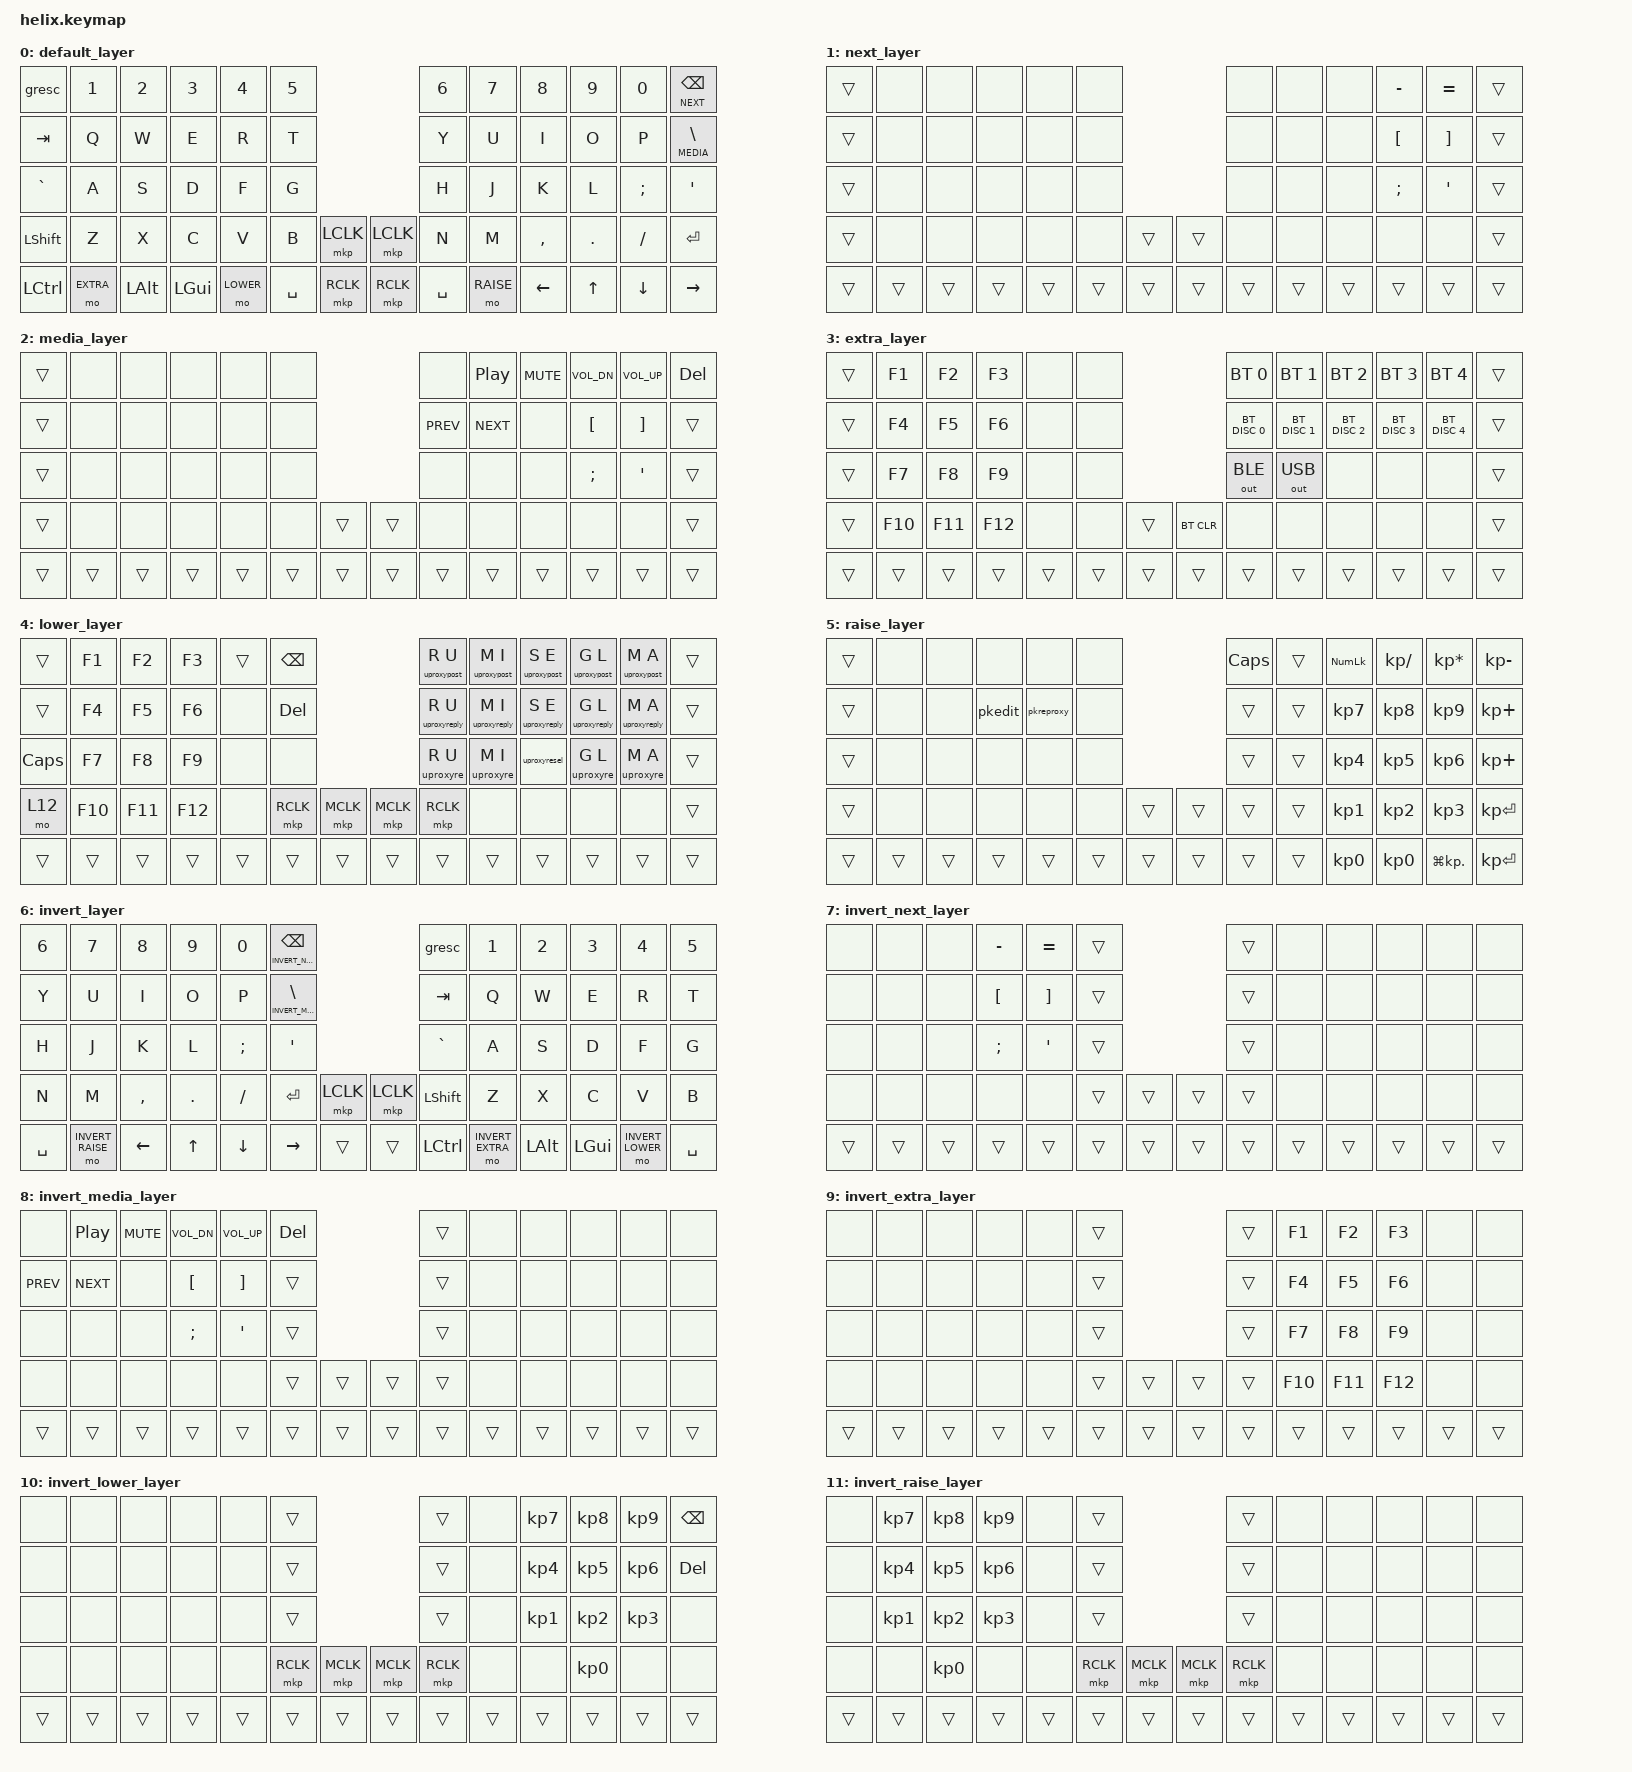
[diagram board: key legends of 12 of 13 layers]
/*
 * Copyright (c) 2020 The ZMK Contributors
 *
 * SPDX-License-Identifier: MIT
 */

#include <dt-bindings/zmk/mouse.h>
#include <behaviors.dtsi>
#include <dt-bindings/zmk/bt.h>
#include <dt-bindings/zmk/keys.h>
#include <dt-bindings/zmk/outputs.h>
#include <dt-bindings/zmk/pointing.h>

#define DEFAULT 0
#define NEXT 1
#define MEDIA 2
#define EXTRA 3
#define LOWER  4
#define RAISE  5
#define INVERT 6
#define INVERT_NEXT 7
#define INVERT_MEDIA 8
#define INVERT_EXTRA 9
#define INVERT_LOWER 10
#define INVERT_RAISE 11

/ {
    macros {
        qmaddie: qmaddie {
            compatible = "zmk,behavior-macro";
            #binding-cells = <0>;
            bindings = <&kp M &kp A &kp D &kp D &kp I &kp E &kp COLON &kp RET &kp GT &kp SPACE>;
            label = "QMADDIE";
        };

        qruby: qruby {
            compatible = "zmk,behavior-macro";
            #binding-cells = <0>;
            bindings = <&kp LS(R) &kp U &kp B &kp Y &kp COLON &kp RET &kp GT &kp SPACE>;
            label = "QRUBY";
        };

        qglimmer: qglimmer {
            compatible = "zmk,behavior-macro";
            #binding-cells = <0>;
            bindings = <&kp LS(G) &kp L &kp I &kp M &kp M &kp E &kp R &kp COLON &kp RET &kp GT &kp SPACE>;
            label = "QGLIMMER";
        };

        qselphie: qselphie {
            compatible = "zmk,behavior-macro";
            #binding-cells = <0>;
            bindings = <&kp LS(S) &kp E &kp L &kp P &kp H &kp I &kp E &kp COLON &kp RET &kp GT &kp SPACE>;
            label = "QSELPHIE";
        };

        qmio: qmio {
            compatible = "zmk,behavior-macro";
            #binding-cells = <0>;
            bindings = <&kp LS(M) &kp I &kp O &kp COLON &kp RET &kp GT &kp SPACE>;
            label = "QMIO";
        };

        pkreproxy: pkreproxy {
            compatible = "zmk,behavior-macro";
            #binding-cells = <0>;
            bindings = <&kp P &kp K &kp SEMI &kp R &kp E &kp P &kp R &kp O &kp X &kp Y &kp SPACE>;
            label = "PKREPROXY";
        };

        pkedit: pkedit {
            compatible = "zmk,behavior-macro";
            #binding-cells = <0>;
            bindings = <&kp P &kp K &kp SEMI &kp E &kp SPACE>;
            label = "PKEDIT";
        };

        pkremaddie: pkremaddie {
            compatible = "zmk,behavior-macro";
            #binding-cells = <0>;
            bindings = <&pkreproxy &kp M &kp A &kp D &kp D &kp I &kp E &kp RET>;
            label = "PKREMADDIE";
        };

        pkreglimmer: pkreglimmer {
            compatible = "zmk,behavior-macro";
            #binding-cells = <0>;
            bindings = <&pkreproxy &kp G &kp L &kp I &kp M &kp M &kp E &kp R &kp RET>;
            label = "PKREGLIMMER";
        };

        pkreselphie: pkreselphie {
            compatible = "zmk,behavior-macro";
            #binding-cells = <0>;
            bindings = <&pkreproxy &kp S &kp E &kp L &kp P &kp H &kp I &kp E &kp RET>;
            label = "PKRESELPHIE";
        };

        pkremio: pkremio {
            compatible = "zmk,behavior-macro";
            #binding-cells = <0>;
            bindings = <&pkreproxy &kp M &kp I &kp O &kp RET>;
            label = "PKREMIO";
        };

        pkreruby: pkreruby {
            compatible = "zmk,behavior-macro";
            #binding-cells = <0>;
            bindings = <&pkreproxy &kp R &kp U &kp B &kp Y &kp RET>;
            label = "PKRERUBY";
        };

        uproxyreply: uproxy {
            compatible = "zmk,behavior-macro-two-param";
            #binding-cells = <2>;
            bindings = <&kp FSLH &macro_param_1to1 &kp MACRO_PLACEHOLDER &macro_param_2to1 &kp MACRO_PLACEHOLDER &kp TAB &kp Q &kp TAB &kp T &kp TAB &kp M &kp TAB>;
            label = "UPROXY";
        };

        uproxypost: uproxypost {
            compatible = "zmk,behavior-macro-two-param";
            #binding-cells = <2>;
            bindings = <&kp FSLH &macro_param_1to1 &kp MACRO_PLACEHOLDER &macro_param_2to1 &kp MACRO_PLACEHOLDER &kp TAB &kp M &kp TAB>;
            label = "UPROXYPOST";
        };

        uproxyre: uproxyre {
            compatible = "zmk,behavior-macro-two-param";
            #binding-cells = <2>;
            bindings = <&kp FSLH &kp R &kp E &kp P &kp R &kp O &kp X &kp Y &kp TAB &macro_param_1to1 &kp MACRO_PLACEHOLDER &macro_param_2to1 &kp MACRO_PLACEHOLDER>;
            label = "UPROXYRE";
        };

        uproxyresel: uproxyresel {
            compatible = "zmk,behavior-macro";
            #binding-cells = <0>;
            bindings = <&uproxyre S E &kp L>;
            label = "UPROXYRESEL";
        };

        pkproxy: pkproxy {
            compatible = "zmk,behavior-macro-one-param";
            #binding-cells = <1>;
            bindings = <&kp AMPERSAND &macro_param_1to1 &kp MACRO_PLACEHOLDER>;
            label = "PKPROXY";
        };
    };

    keymap {
        compatible = "zmk,keymap";

        default_layer {
            bindings = <
&gresc     &kp N1     &kp N2    &kp N3    &kp N4     &kp N5                             &kp N6     &kp N7     &kp N8     &kp N9      &kp N0     &lt NEXT BSPC
&kp TAB    &kp Q      &kp W     &kp E     &kp R      &kp T                              &kp Y      &kp U      &kp I      &kp O       &kp P      &lt MEDIA BSLH
&kp GRAVE  &kp A      &kp S     &kp D     &kp F      &kp G                              &kp H      &kp J      &kp K      &kp L       &kp SEMI   &kp SQT
&kp LSHFT  &kp Z      &kp X     &kp C     &kp V      &kp B      &mkp LCLK    &mkp LCLK  &kp N      &kp M      &kp COMMA  &kp PERIOD  &kp SLASH  &kp RET
&kp LCTRL  &mo EXTRA  &kp LALT  &kp LGUI  &mo LOWER  &kp SPACE  &mkp RCLK    &mkp RCLK  &kp SPACE  &mo RAISE  &kp LEFT   &kp UP      &kp DOWN   &kp RIGHT
            >;
        };

        next_layer {
            bindings = <
&trans  &none   &none   &none   &none   &none                     &none   &none   &none   &kp MINUS  &kp EQUAL  &trans
&trans  &none   &none   &none   &none   &none                     &none   &none   &none   &kp LBKT   &kp RBKT   &trans
&trans  &none   &none   &none   &none   &none                     &none   &none   &none   &kp SEMI   &kp SQT    &trans
&trans  &none   &none   &none   &none   &none   &trans    &trans  &none   &none   &none   &none      &none      &trans
&trans  &trans  &trans  &trans  &trans  &trans  &trans    &trans  &trans  &trans  &trans  &trans     &trans     &trans
            >;
        };

        media_layer {
            bindings = <
&trans  &none   &none   &none   &none   &none                     &none       &kp C_PLAY_PAUSE  &kp C_MUTE  &kp C_VOL_DN  &kp C_VOL_UP  &kp DEL
&trans  &none   &none   &none   &none   &none                     &kp C_PREV  &kp C_NEXT        &none       &kp LBKT      &kp RBKT      &trans
&trans  &none   &none   &none   &none   &none                     &none       &none             &none       &kp SEMI      &kp SQT       &trans
&trans  &none   &none   &none   &none   &none   &trans    &trans  &none       &none             &none       &none         &none         &trans
&trans  &trans  &trans  &trans  &trans  &trans  &trans    &trans  &trans      &trans            &trans      &trans        &trans        &trans
            >;
        };

        extra_layer {
            bindings = <
&trans  &kp F1   &kp F2   &kp F3   &none   &none                         &bt BT_SEL 0   &bt BT_SEL 1   &bt BT_SEL 2   &bt BT_SEL 3   &bt BT_SEL 4   &trans
&trans  &kp F4   &kp F5   &kp F6   &none   &none                         &bt BT_DISC 0  &bt BT_DISC 1  &bt BT_DISC 2  &bt BT_DISC 3  &bt BT_DISC 4  &trans
&trans  &kp F7   &kp F8   &kp F9   &none   &none                         &out OUT_BLE   &out OUT_USB   &none          &none          &none          &trans
&trans  &kp F10  &kp F11  &kp F12  &none   &none   &trans    &bt BT_CLR  &none          &none          &none          &none          &none          &trans
&trans  &trans   &trans   &trans   &trans  &trans  &trans    &trans      &trans         &trans         &trans         &trans         &trans         &trans
            >;
        };

        lower_layer {
            bindings = <
&trans    &kp F1   &kp F2   &kp F3   &trans  &kp BSPC                           &uproxypost R U   &uproxypost M I   &uproxypost S E   &uproxypost G L   &uproxypost M A   &trans
&trans    &kp F4   &kp F5   &kp F6   &none   &kp DEL                            &uproxyreply R U  &uproxyreply M I  &uproxyreply S E  &uproxyreply G L  &uproxyreply M A  &trans
&kp CLCK  &kp F7   &kp F8   &kp F9   &none   &none                              &uproxyre R U     &uproxyre M I     &uproxyresel      &uproxyre G L     &uproxyre M A     &trans
&mo 12    &kp F10  &kp F11  &kp F12  &none   &mkp RCLK  &mkp MCLK    &mkp MCLK  &mkp RCLK         &none             &none             &none             &none             &trans
&trans    &trans   &trans   &trans   &trans  &trans     &trans       &trans     &trans            &trans            &trans            &trans            &trans            &trans
            >;
        };

        raise_layer {
            bindings = <
&trans  &none   &none   &none    &none       &none                     &kp CAPSLOCK  &trans  &kp KP_NUMLOCK   &kp KP_DIVIDE    &kp KP_MULTIPLY  &kp KP_MINUS
&trans  &none   &none   &pkedit  &pkreproxy  &none                     &trans        &trans  &kp KP_NUMBER_7  &kp KP_NUMBER_8  &kp KP_NUMBER_9  &kp KP_PLUS
&trans  &none   &none   &none    &none       &none                     &trans        &trans  &kp KP_NUMBER_4  &kp KP_NUMBER_5  &kp KP_NUMBER_6  &kp KP_PLUS
&trans  &none   &none   &none    &none       &none   &trans    &trans  &trans        &trans  &kp KP_N1        &kp KP_NUMBER_2  &kp KP_N3        &kp KP_ENTER
&trans  &trans  &trans  &trans   &trans      &trans  &trans    &trans  &trans        &trans  &kp KP_N0        &kp KP_NUMBER_0  &kp LG(KP_DOT)   &kp KP_ENTER
            >;
        };

        invert_layer {
            bindings = <
&kp N6     &kp N7            &kp N8     &kp N9      &kp N0     &lt INVERT_NEXT BSPC                           &gresc     &kp N1            &kp N2    &kp N3    &kp N4            &kp N5
&kp Y      &kp U             &kp I      &kp O       &kp P      &lt INVERT_MEDIA BSLH                          &kp TAB    &kp Q             &kp W     &kp E     &kp R             &kp T
&kp H      &kp J             &kp K      &kp L       &kp SEMI   &kp SQT                                        &kp GRAVE  &kp A             &kp S     &kp D     &kp F             &kp G
&kp N      &kp M             &kp COMMA  &kp PERIOD  &kp SLASH  &kp RET                &mkp LCLK    &mkp LCLK  &kp LSHFT  &kp Z             &kp X     &kp C     &kp V             &kp B
&kp SPACE  &mo INVERT_RAISE  &kp LEFT   &kp UP      &kp DOWN   &kp RIGHT              &trans       &trans     &kp LCTRL  &mo INVERT_EXTRA  &kp LALT  &kp LGUI  &mo INVERT_LOWER  &kp SPACE
            >;
        };

        invert_next_layer {
            bindings = <
&none   &none   &none   &kp MINUS  &kp EQUAL  &trans                    &trans  &none   &none   &none   &none   &none
&none   &none   &none   &kp LBKT   &kp RBKT   &trans                    &trans  &none   &none   &none   &none   &none
&none   &none   &none   &kp SEMI   &kp SQT    &trans                    &trans  &none   &none   &none   &none   &none
&none   &none   &none   &none      &none      &trans  &trans    &trans  &trans  &none   &none   &none   &none   &none
&trans  &trans  &trans  &trans     &trans     &trans  &trans    &trans  &trans  &trans  &trans  &trans  &trans  &trans
            >;
        };

        invert_media_layer {
            bindings = <
&none       &kp C_PLAY_PAUSE  &kp C_MUTE  &kp C_VOL_DN  &kp C_VOL_UP  &kp DEL                    &trans  &none   &none   &none   &none   &none
&kp C_PREV  &kp C_NEXT        &none       &kp LBKT      &kp RBKT      &trans                     &trans  &none   &none   &none   &none   &none
&none       &none             &none       &kp SEMI      &kp SQT       &trans                     &trans  &none   &none   &none   &none   &none
&none       &none             &none       &none         &none         &trans   &trans    &trans  &trans  &none   &none   &none   &none   &none
&trans      &trans            &trans      &trans        &trans        &trans   &trans    &trans  &trans  &trans  &trans  &trans  &trans  &trans
            >;
        };

        invert_extra_layer {
            bindings = <
&none   &none   &none   &none   &none   &trans                    &trans  &kp F1   &kp F2   &kp F3   &none   &none
&none   &none   &none   &none   &none   &trans                    &trans  &kp F4   &kp F5   &kp F6   &none   &none
&none   &none   &none   &none   &none   &trans                    &trans  &kp F7   &kp F8   &kp F9   &none   &none
&none   &none   &none   &none   &none   &trans  &trans    &trans  &trans  &kp F10  &kp F11  &kp F12  &none   &none
&trans  &trans  &trans  &trans  &trans  &trans  &trans    &trans  &trans  &trans   &trans   &trans   &trans  &trans
            >;
        };

        invert_lower_layer {
            bindings = <
&none   &none   &none   &none   &none   &trans                             &trans     &none   &kp KP_N7  &kp KP_N8  &kp KP_N9  &kp BSPC
&none   &none   &none   &none   &none   &trans                             &trans     &none   &kp KP_N4  &kp KP_N5  &kp KP_N6  &kp DEL
&none   &none   &none   &none   &none   &trans                             &trans     &none   &kp KP_N1  &kp KP_N2  &kp KP_N3  &none
&none   &none   &none   &none   &none   &mkp RCLK  &mkp MCLK    &mkp MCLK  &mkp RCLK  &none   &none      &kp KP_N0  &none      &none
&trans  &trans  &trans  &trans  &trans  &trans     &trans       &trans     &trans     &trans  &trans     &trans     &trans     &trans
            >;
        };

        invert_raise_layer {
            bindings = <
&none   &kp KP_N7  &kp KP_N8  &kp KP_N9  &none   &trans                             &trans     &none   &none   &none   &none   &none
&none   &kp KP_N4  &kp KP_N5  &kp KP_N6  &none   &trans                             &trans     &none   &none   &none   &none   &none
&none   &kp KP_N1  &kp KP_N2  &kp KP_N3  &none   &trans                             &trans     &none   &none   &none   &none   &none
&none   &none      &kp KP_N0  &none      &none   &mkp RCLK  &mkp MCLK    &mkp MCLK  &mkp RCLK  &none   &none   &none   &none   &none
&trans  &trans     &trans     &trans     &trans  &trans     &trans       &trans     &trans     &trans  &trans  &trans  &trans  &trans
            >;
        };

        lower_shift {
            bindings = <
&trans  &trans  &trans  &trans  &trans  &trans                    &pkreruby  &pkremio  &pkreselphie  &pkreglimmer  &pkremaddie  &trans
&trans  &trans  &trans  &trans  &trans  &trans                    &trans     &trans    &trans        &trans        &trans       &trans
&trans  &trans  &trans  &trans  &trans  &trans                    &trans     &trans    &trans        &trans        &trans       &trans
&trans  &trans  &trans  &trans  &trans  &trans  &trans    &trans  &trans     &trans    &trans        &trans        &trans       &trans
&trans  &trans  &trans  &trans  &trans  &trans  &trans    &trans  &trans     &trans    &trans        &trans        &trans       &trans
            >;
        };
    };
};
